AUTOSAR XML (schema 4-2-2)
package /ComponentTypes
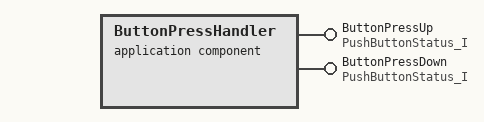
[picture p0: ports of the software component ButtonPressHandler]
  application sw component type ButtonPressHandler
    provide port ButtonPressUp: queued-sender-com-spec=PushButtonStatus, provided-interface=PushButtonStatus_I
    provide port ButtonPressDown: queued-sender-com-spec=PushButtonStatus, provided-interface=PushButtonStatus_I
    behavior ButtonPressHandler_InternalBehavior
      port-api-options:
        enable-take-address=false, indirect-api=false, port=ButtonPressDown
        enable-take-address=false, indirect-api=false, port=ButtonPressUp
  swc implementation ButtonPressHandler_Implementation: behavior=ButtonPressHandler_InternalBehavior
    code-descriptors:
      code Default: artifact-descriptors=autosar-engineering-object={short-label=Default, category=SWSRC}
